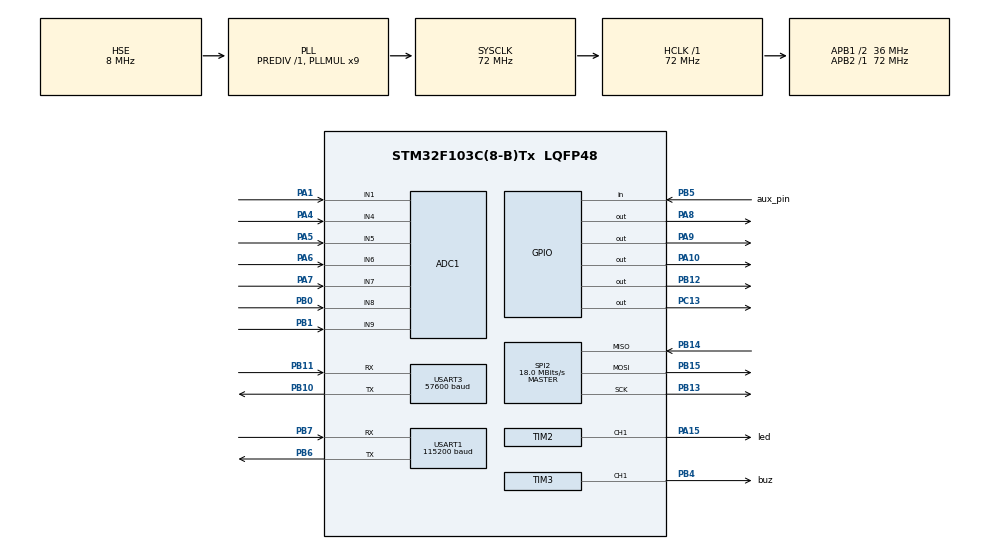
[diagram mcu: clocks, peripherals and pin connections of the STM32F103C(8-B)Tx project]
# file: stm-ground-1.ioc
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ADC1.Channel-1\#ChannelRegularConversion=ADC_CHANNEL_VREFINT
ADC1.Channel-2\#ChannelRegularConversion=ADC_CHANNEL_4
ADC1.Channel-3\#ChannelRegularConversion=ADC_CHANNEL_5
ADC1.Channel-4\#ChannelRegularConversion=ADC_CHANNEL_6
ADC1.Channel-5\#ChannelRegularConversion=ADC_CHANNEL_7
ADC1.Channel-6\#ChannelRegularConversion=ADC_CHANNEL_8
ADC1.Channel-7\#ChannelRegularConversion=ADC_CHANNEL_9
ADC1.Channel-8\#ChannelRegularConversion=ADC_CHANNEL_1
ADC1.NbrOfConversion=8
ADC1.NbrOfConversionFlag=1
ADC1.Rank-1\#ChannelRegularConversion=1
ADC1.Rank-2\#ChannelRegularConversion=2
ADC1.Rank-3\#ChannelRegularConversion=3
ADC1.Rank-4\#ChannelRegularConversion=4
ADC1.Rank-5\#ChannelRegularConversion=5
ADC1.Rank-6\#ChannelRegularConversion=6
ADC1.Rank-7\#ChannelRegularConversion=7
ADC1.Rank-8\#ChannelRegularConversion=8
ADC1.SamplingTime-1\#ChannelRegularConversion=ADC_SAMPLETIME_41CYCLES_5
ADC1.SamplingTime-2\#ChannelRegularConversion=ADC_SAMPLETIME_41CYCLES_5
ADC1.SamplingTime-3\#ChannelRegularConversion=ADC_SAMPLETIME_41CYCLES_5
ADC1.SamplingTime-4\#ChannelRegularConversion=ADC_SAMPLETIME_41CYCLES_5
ADC1.SamplingTime-5\#ChannelRegularConversion=ADC_SAMPLETIME_41CYCLES_5
ADC1.SamplingTime-6\#ChannelRegularConversion=ADC_SAMPLETIME_41CYCLES_5
ADC1.SamplingTime-7\#ChannelRegularConversion=ADC_SAMPLETIME_41CYCLES_5
ADC1.SamplingTime-8\#ChannelRegularConversion=ADC_SAMPLETIME_41CYCLES_5
ADC1.master=1
Dma.ADC1.1.Direction=DMA_PERIPH_TO_MEMORY
Dma.ADC1.1.Instance=DMA1_Channel1
Dma.ADC1.1.MemDataAlignment=DMA_MDATAALIGN_HALFWORD
Dma.ADC1.1.MemInc=DMA_MINC_ENABLE
Dma.ADC1.1.Mode=DMA_NORMAL
Dma.ADC1.1.PeriphDataAlignment=DMA_PDATAALIGN_HALFWORD
Dma.ADC1.1.PeriphInc=DMA_PINC_DISABLE
Dma.ADC1.1.Priority=DMA_PRIORITY_LOW
Dma.Request0=SPI2_TX
Dma.Request1=ADC1
Dma.SPI2_TX.0.Direction=DMA_MEMORY_TO_PERIPH
Dma.SPI2_TX.0.Instance=DMA1_Channel5
Dma.SPI2_TX.0.MemDataAlignment=DMA_MDATAALIGN_BYTE
Dma.SPI2_TX.0.MemInc=DMA_MINC_ENABLE
Dma.SPI2_TX.0.Mode=DMA_NORMAL
Dma.SPI2_TX.0.PeriphDataAlignment=DMA_PDATAALIGN_BYTE
Dma.SPI2_TX.0.PeriphInc=DMA_PINC_DISABLE
Dma.SPI2_TX.0.Priority=DMA_PRIORITY_LOW
Mcu.Family=STM32F1
Mcu.Name=STM32F103C(8-B)Tx
Mcu.Package=LQFP48
NVIC.DMA1_Channel1_IRQn=true\:0\:0\:false\:false\:true\:false\:true\:true
NVIC.DMA1_Channel5_IRQn=true\:0\:0\:false\:false\:true\:false\:true\:true
NVIC.PriorityGroup=NVIC_PRIORITYGROUP_4
NVIC.SPI2_IRQn=true\:0\:0\:false\:false\:true\:true\:true\:true
NVIC.TIM2_IRQn=true\:0\:0\:false\:false\:true\:true\:true\:true
NVIC.USART1_IRQn=true\:0\:0\:false\:false\:true\:true\:true\:true
NVIC.USART3_IRQn=true\:0\:0\:false\:false\:true\:true\:true\:true
PA1.Signal=ADCx_IN1
PA10.Signal=GPIO_Output
PA13.Mode=Trace_Asynchronous_SW
PA13.Signal=SYS_JTMS-SWDIO
PA14.Mode=Trace_Asynchronous_SW
PA14.Signal=SYS_JTCK-SWCLK
PA15.GPIO_Label=led
PA15.Signal=S_TIM2_CH1_ETR
PA4.Signal=ADCx_IN4
PA5.Signal=ADCx_IN5
PA6.Signal=ADCx_IN6
PA7.Signal=ADCx_IN7
PA8.Signal=GPIO_Output
PA9.Signal=GPIO_Output
PB0.Signal=ADCx_IN8
PB1.Signal=ADCx_IN9
PB10.Mode=Asynchronous
PB10.Signal=USART3_TX
PB11.Mode=Asynchronous
PB11.Signal=USART3_RX
PB12.Signal=GPIO_Output
PB13.Mode=Full_Duplex_Master
PB13.Signal=SPI2_SCK
PB14.Mode=Full_Duplex_Master
PB14.Signal=SPI2_MISO
PB15.Mode=Full_Duplex_Master
PB15.Signal=SPI2_MOSI
PB3.Mode=Trace_Asynchronous_SW
PB3.Signal=SYS_JTDO-TRACESWO
PB4.GPIO_Label=buz
PB4.Signal=S_TIM3_CH1
PB5.GPIO_Label=aux_pin
PB5.Signal=GPIO_Input
PB6.Mode=Asynchronous
PB6.Signal=USART1_TX
PB7.Mode=Asynchronous
PB7.Signal=USART1_RX
PC13-TAMPER-RTC.Signal=GPIO_Output
PD0-OSC_IN.Mode=HSE-External-Oscillator
PD0-OSC_IN.Signal=RCC_OSC_IN
PD1-OSC_OUT.Mode=HSE-External-Oscillator
PD1-OSC_OUT.Signal=RCC_OSC_OUT
ProjectManager.HeapSize=0x200
ProjectManager.StackSize=0x400
ProjectManager.TargetToolchain=STM32CubeIDE
RCC.ADCPresc=RCC_ADCPCLK2_DIV6
RCC.AHBFreq_Value=72000000
RCC.APB1CLKDivider=RCC_HCLK_DIV2
RCC.APB1Freq_Value=36000000
RCC.APB1TimFreq_Value=72000000
RCC.APB2Freq_Value=72000000
RCC.APB2TimFreq_Value=72000000
RCC.HCLKFreq_Value=72000000
RCC.PLLMUL=RCC_PLL_MUL9
RCC.PLLSourceVirtual=RCC_PLLSOURCE_HSE
RCC.SYSCLKFreq_VALUE=72000000
RCC.SYSCLKSource=RCC_SYSCLKSOURCE_PLLCLK
RCC.USBFreq_Value=72000000
SH.ADCx_IN1.0=ADC1_IN1,IN1
SH.ADCx_IN4.0=ADC1_IN4,IN4
SH.ADCx_IN5.0=ADC1_IN5,IN5
SH.ADCx_IN6.0=ADC1_IN6,IN6
SH.ADCx_IN7.0=ADC1_IN7,IN7
SH.ADCx_IN8.0=ADC1_IN8,IN8
SH.ADCx_IN9.0=ADC1_IN9,IN9
SH.S_TIM2_CH1_ETR.0=TIM2_CH1,PWM Generation1 CH1
SH.S_TIM3_CH1.0=TIM3_CH1,PWM Generation1 CH1
SPI2.BaudRatePrescaler=SPI_BAUDRATEPRESCALER_2
SPI2.CLKPolarity=SPI_POLARITY_LOW
SPI2.CalculateBaudRate=18.0 MBits/s
SPI2.Direction=SPI_DIRECTION_2LINES
SPI2.Mode=SPI_MODE_MASTER
SPI2.VirtualType=VM_MASTER
TIM2.Channel-PWM\ Generation1\ CH1=TIM_CHANNEL_1
TIM2.Period=999
TIM2.Prescaler=71
TIM3.Channel-PWM\ Generation1\ CH1=TIM_CHANNEL_1
TIM3.Period=249
TIM3.Prescaler=71
USART1.BaudRate=115200
USART1.VirtualMode=VM_ASYNC
USART3.BaudRate=57600
USART3.VirtualMode=VM_ASYNC
VP_ADC1_Vref_Input.Mode=IN-Vrefint
VP_TIM2_VS_ClockSourceINT.Mode=Internal
VP_TIM3_VS_ClockSourceINT.Mode=Internal
board=custom

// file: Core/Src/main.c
/* USER CODE BEGIN Header */
/**
  ******************************************************************************
  * @file           : main.c
  * @brief          : Main program body
  ******************************************************************************
  * @attention
  *
  * Copyright (c) 2025 STMicroelectronics.
  * All rights reserved.
  *
  * This software is licensed under terms that can be found in the LICENSE file
  * in the root directory of this software component.
  * If no LICENSE file comes with this software, it is provided AS-IS.
  *
  ******************************************************************************
  */
/* USER CODE END Header */
#include "main.h"

/* USER CODE BEGIN PTD */
int app();
__attribute__((weak)) int _write(int file, char* ptr, int len)
{
    (void)file;
    int DataIdx;

    for (DataIdx = 0; DataIdx < len; DataIdx++)
    {
        ITM_SendChar(*ptr++);
    }
    return len;
}
/* USER CODE END PTD */

ADC_HandleTypeDef hadc1;
DMA_HandleTypeDef hdma_adc1;

SPI_HandleTypeDef hspi2;
DMA_HandleTypeDef hdma_spi2_tx;

TIM_HandleTypeDef htim2;
TIM_HandleTypeDef htim3;

UART_HandleTypeDef huart1;
UART_HandleTypeDef huart3;

void SystemClock_Config(void);
static void MX_GPIO_Init(void);
static void MX_DMA_Init(void);
static void MX_SPI2_Init(void);
static void MX_USART1_UART_Init(void);
static void MX_ADC1_Init(void);
static void MX_USART3_UART_Init(void);
static void MX_TIM2_Init(void);
static void MX_TIM3_Init(void);

int main(void)
{

  /* MCU Configuration--------------------------------------------------------*/

  /* Reset of all peripherals, Initializes the Flash interface and the Systick. */
  HAL_Init();

  /* Configure the system clock */
  SystemClock_Config();

  /* Initialize all configured peripherals */
  MX_GPIO_Init();
  MX_DMA_Init();
  MX_SPI2_Init();
  MX_USART1_UART_Init();
  MX_ADC1_Init();
  MX_USART3_UART_Init();
  MX_TIM2_Init();
  MX_TIM3_Init();
  /* USER CODE BEGIN 2 */
  app();
  /* USER CODE END 2 */

  /* Infinite loop */
  while (1)
  {

  }
}

void SystemClock_Config(void)
{
  RCC_OscInitTypeDef RCC_OscInitStruct = {0};
  RCC_ClkInitTypeDef RCC_ClkInitStruct = {0};
  RCC_PeriphCLKInitTypeDef PeriphClkInit = {0};

  /** Initializes the RCC Oscillators according to the specified parameters
  * in the RCC_OscInitTypeDef structure.
  */
  RCC_OscInitStruct.OscillatorType = RCC_OSCILLATORTYPE_HSE;
  RCC_OscInitStruct.HSEState = RCC_HSE_ON;
  RCC_OscInitStruct.HSEPredivValue = RCC_HSE_PREDIV_DIV1;
  RCC_OscInitStruct.HSIState = RCC_HSI_ON;
  RCC_OscInitStruct.PLL.PLLState = RCC_PLL_ON;
  RCC_OscInitStruct.PLL.PLLSource = RCC_PLLSOURCE_HSE;
  RCC_OscInitStruct.PLL.PLLMUL = RCC_PLL_MUL9;
  if (HAL_RCC_OscConfig(&RCC_OscInitStruct) != HAL_OK)
  {
    Error_Handler();
  }

  /** Initializes the CPU, AHB and APB buses clocks
  */
  RCC_ClkInitStruct.ClockType = RCC_CLOCKTYPE_HCLK|RCC_CLOCKTYPE_SYSCLK
                              |RCC_CLOCKTYPE_PCLK1|RCC_CLOCKTYPE_PCLK2;
  RCC_ClkInitStruct.SYSCLKSource = RCC_SYSCLKSOURCE_PLLCLK;
  RCC_ClkInitStruct.AHBCLKDivider = RCC_SYSCLK_DIV1;
  RCC_ClkInitStruct.APB1CLKDivider = RCC_HCLK_DIV2;
  RCC_ClkInitStruct.APB2CLKDivider = RCC_HCLK_DIV1;

  if (HAL_RCC_ClockConfig(&RCC_ClkInitStruct, FLASH_LATENCY_2) != HAL_OK)
  {
    Error_Handler();
  }
  PeriphClkInit.PeriphClockSelection = RCC_PERIPHCLK_ADC;
  PeriphClkInit.AdcClockSelection = RCC_ADCPCLK2_DIV6;
  if (HAL_RCCEx_PeriphCLKConfig(&PeriphClkInit) != HAL_OK)
  {
    Error_Handler();
  }
}

static void MX_ADC1_Init(void)
{

  ADC_ChannelConfTypeDef sConfig = {0};

  /** Common config
  */
  hadc1.Instance = ADC1;
  hadc1.Init.ScanConvMode = ADC_SCAN_ENABLE;
  hadc1.Init.ContinuousConvMode = DISABLE;
  hadc1.Init.DiscontinuousConvMode = DISABLE;
  hadc1.Init.ExternalTrigConv = ADC_SOFTWARE_START;
  hadc1.Init.DataAlign = ADC_DATAALIGN_RIGHT;
  hadc1.Init.NbrOfConversion = 8;
  if (HAL_ADC_Init(&hadc1) != HAL_OK)
  {
    Error_Handler();
  }

  /** Configure Regular Channel
  */
  sConfig.Channel = ADC_CHANNEL_VREFINT;
  sConfig.Rank = ADC_REGULAR_RANK_1;
  sConfig.SamplingTime = ADC_SAMPLETIME_41CYCLES_5;
  if (HAL_ADC_ConfigChannel(&hadc1, &sConfig) != HAL_OK)
  {
    Error_Handler();
  }

  /** Configure Regular Channel
  */
  sConfig.Channel = ADC_CHANNEL_4;
  sConfig.Rank = ADC_REGULAR_RANK_2;
  if (HAL_ADC_ConfigChannel(&hadc1, &sConfig) != HAL_OK)
  {
    Error_Handler();
  }

  /** Configure Regular Channel
  */
  sConfig.Channel = ADC_CHANNEL_5;
  sConfig.Rank = ADC_REGULAR_RANK_3;
  if (HAL_ADC_ConfigChannel(&hadc1, &sConfig) != HAL_OK)
  {
    Error_Handler();
  }

  /** Configure Regular Channel
  */
  sConfig.Channel = ADC_CHANNEL_6;
  sConfig.Rank = ADC_REGULAR_RANK_4;
  if (HAL_ADC_ConfigChannel(&hadc1, &sConfig) != HAL_OK)
  {
    Error_Handler();
  }

  /** Configure Regular Channel
  */
  sConfig.Channel = ADC_CHANNEL_7;
  sConfig.Rank = ADC_REGULAR_RANK_5;
  if (HAL_ADC_ConfigChannel(&hadc1, &sConfig) != HAL_OK)
  {
    Error_Handler();
  }

  /** Configure Regular Channel
  */
  sConfig.Channel = ADC_CHANNEL_8;
  sConfig.Rank = ADC_REGULAR_RANK_6;
  if (HAL_ADC_ConfigChannel(&hadc1, &sConfig) != HAL_OK)
  {
    Error_Handler();
  }

  /** Configure Regular Channel
  */
  sConfig.Channel = ADC_CHANNEL_9;
  sConfig.Rank = ADC_REGULAR_RANK_7;
  if (HAL_ADC_ConfigChannel(&hadc1, &sConfig) != HAL_OK)
  {
    Error_Handler();
  }

  /** Configure Regular Channel
  */
  sConfig.Channel = ADC_CHANNEL_1;
  sConfig.Rank = ADC_REGULAR_RANK_8;
  if (HAL_ADC_ConfigChannel(&hadc1, &sConfig) != HAL_OK)
  {
    Error_Handler();
  }

}

static void MX_SPI2_Init(void)
{

  /* SPI2 parameter configuration*/
  hspi2.Instance = SPI2;
  hspi2.Init.Mode = SPI_MODE_MASTER;
  hspi2.Init.Direction = SPI_DIRECTION_2LINES;
  hspi2.Init.DataSize = SPI_DATASIZE_8BIT;
  hspi2.Init.CLKPolarity = SPI_POLARITY_LOW;
  hspi2.Init.CLKPhase = SPI_PHASE_1EDGE;
  hspi2.Init.NSS = SPI_NSS_SOFT;
  hspi2.Init.BaudRatePrescaler = SPI_BAUDRATEPRESCALER_2;
  hspi2.Init.FirstBit = SPI_FIRSTBIT_MSB;
  hspi2.Init.TIMode = SPI_TIMODE_DISABLE;
  hspi2.Init.CRCCalculation = SPI_CRCCALCULATION_DISABLE;
  hspi2.Init.CRCPolynomial = 10;
  if (HAL_SPI_Init(&hspi2) != HAL_OK)
  {
    Error_Handler();
  }

}

static void MX_TIM2_Init(void)
{

  TIM_ClockConfigTypeDef sClockSourceConfig = {0};
  TIM_MasterConfigTypeDef sMasterConfig = {0};
  TIM_OC_InitTypeDef sConfigOC = {0};

  htim2.Instance = TIM2;
  htim2.Init.Prescaler = 71;
  htim2.Init.CounterMode = TIM_COUNTERMODE_UP;
  htim2.Init.Period = 999;
  htim2.Init.ClockDivision = TIM_CLOCKDIVISION_DIV1;
  htim2.Init.AutoReloadPreload = TIM_AUTORELOAD_PRELOAD_DISABLE;
  if (HAL_TIM_Base_Init(&htim2) != HAL_OK)
  {
    Error_Handler();
  }
  sClockSourceConfig.ClockSource = TIM_CLOCKSOURCE_INTERNAL;
  if (HAL_TIM_ConfigClockSource(&htim2, &sClockSourceConfig) != HAL_OK)
  {
    Error_Handler();
  }
  if (HAL_TIM_PWM_Init(&htim2) != HAL_OK)
  {
    Error_Handler();
  }
  sMasterConfig.MasterOutputTrigger = TIM_TRGO_RESET;
  sMasterConfig.MasterSlaveMode = TIM_MASTERSLAVEMODE_DISABLE;
  if (HAL_TIMEx_MasterConfigSynchronization(&htim2, &sMasterConfig) != HAL_OK)
  {
    Error_Handler();
  }
  sConfigOC.OCMode = TIM_OCMODE_PWM1;
  sConfigOC.Pulse = 0;
  sConfigOC.OCPolarity = TIM_OCPOLARITY_HIGH;
  sConfigOC.OCFastMode = TIM_OCFAST_DISABLE;
  if (HAL_TIM_PWM_ConfigChannel(&htim2, &sConfigOC, TIM_CHANNEL_1) != HAL_OK)
  {
    Error_Handler();
  }
  HAL_TIM_MspPostInit(&htim2);

}

static void MX_TIM3_Init(void)
{

  TIM_ClockConfigTypeDef sClockSourceConfig = {0};
  TIM_MasterConfigTypeDef sMasterConfig = {0};
  TIM_OC_InitTypeDef sConfigOC = {0};

  htim3.Instance = TIM3;
  htim3.Init.Prescaler = 71;
  htim3.Init.CounterMode = TIM_COUNTERMODE_UP;
  htim3.Init.Period = 249;
  htim3.Init.ClockDivision = TIM_CLOCKDIVISION_DIV1;
  htim3.Init.AutoReloadPreload = TIM_AUTORELOAD_PRELOAD_DISABLE;
  if (HAL_TIM_Base_Init(&htim3) != HAL_OK)
  {
    Error_Handler();
  }
  sClockSourceConfig.ClockSource = TIM_CLOCKSOURCE_INTERNAL;
  if (HAL_TIM_ConfigClockSource(&htim3, &sClockSourceConfig) != HAL_OK)
  {
    Error_Handler();
  }
  if (HAL_TIM_PWM_Init(&htim3) != HAL_OK)
  {
    Error_Handler();
  }
  sMasterConfig.MasterOutputTrigger = TIM_TRGO_RESET;
  sMasterConfig.MasterSlaveMode = TIM_MASTERSLAVEMODE_DISABLE;
  if (HAL_TIMEx_MasterConfigSynchronization(&htim3, &sMasterConfig) != HAL_OK)
  {
    Error_Handler();
  }
  sConfigOC.OCMode = TIM_OCMODE_PWM1;
  sConfigOC.Pulse = 0;
  sConfigOC.OCPolarity = TIM_OCPOLARITY_HIGH;
  sConfigOC.OCFastMode = TIM_OCFAST_DISABLE;
  if (HAL_TIM_PWM_ConfigChannel(&htim3, &sConfigOC, TIM_CHANNEL_1) != HAL_OK)
  {
    Error_Handler();
  }
  HAL_TIM_MspPostInit(&htim3);

}

static void MX_USART1_UART_Init(void)
{

  huart1.Instance = USART1;
  huart1.Init.BaudRate = 115200;
  huart1.Init.WordLength = UART_WORDLENGTH_8B;
  huart1.Init.StopBits = UART_STOPBITS_1;
  huart1.Init.Parity = UART_PARITY_NONE;
  huart1.Init.Mode = UART_MODE_TX_RX;
  huart1.Init.HwFlowCtl = UART_HWCONTROL_NONE;
  huart1.Init.OverSampling = UART_OVERSAMPLING_16;
  if (HAL_UART_Init(&huart1) != HAL_OK)
  {
    Error_Handler();
  }

}

static void MX_USART3_UART_Init(void)
{

  huart3.Instance = USART3;
  huart3.Init.BaudRate = 57600;
  huart3.Init.WordLength = UART_WORDLENGTH_8B;
  huart3.Init.StopBits = UART_STOPBITS_1;
  huart3.Init.Parity = UART_PARITY_NONE;
  huart3.Init.Mode = UART_MODE_TX_RX;
  huart3.Init.HwFlowCtl = UART_HWCONTROL_NONE;
  huart3.Init.OverSampling = UART_OVERSAMPLING_16;
  if (HAL_UART_Init(&huart3) != HAL_OK)
  {
    Error_Handler();
  }

}

static void MX_DMA_Init(void)
{

  /* DMA controller clock enable */
  __HAL_RCC_DMA1_CLK_ENABLE();

  /* DMA interrupt init */
  /* DMA1_Channel1_IRQn interrupt configuration */
  HAL_NVIC_SetPriority(DMA1_Channel1_IRQn, 0, 0);
  HAL_NVIC_EnableIRQ(DMA1_Channel1_IRQn);
  /* DMA1_Channel5_IRQn interrupt configuration */
  HAL_NVIC_SetPriority(DMA1_Channel5_IRQn, 0, 0);
  HAL_NVIC_EnableIRQ(DMA1_Channel5_IRQn);

}

static void MX_GPIO_Init(void)
{
  GPIO_InitTypeDef GPIO_InitStruct = {0};

  /* GPIO Ports Clock Enable */
  __HAL_RCC_GPIOC_CLK_ENABLE();
  __HAL_RCC_GPIOD_CLK_ENABLE();
  __HAL_RCC_GPIOA_CLK_ENABLE();
  __HAL_RCC_GPIOB_CLK_ENABLE();

  /*Configure GPIO pin Output Level */
  HAL_GPIO_WritePin(GPIOC, GPIO_PIN_13, GPIO_PIN_RESET);

  /*Configure GPIO pin Output Level */
  HAL_GPIO_WritePin(GPIOB, GPIO_PIN_12, GPIO_PIN_RESET);

  /*Configure GPIO pin Output Level */
  HAL_GPIO_WritePin(GPIOA, GPIO_PIN_8|GPIO_PIN_9|GPIO_PIN_10, GPIO_PIN_RESET);

  /*Configure GPIO pin : PC13 */
  GPIO_InitStruct.Pin = GPIO_PIN_13;
  GPIO_InitStruct.Mode = GPIO_MODE_OUTPUT_PP;
  GPIO_InitStruct.Pull = GPIO_NOPULL;
  GPIO_InitStruct.Speed = GPIO_SPEED_FREQ_LOW;
  HAL_GPIO_Init(GPIOC, &GPIO_InitStruct);

  /*Configure GPIO pin : PB12 */
  GPIO_InitStruct.Pin = GPIO_PIN_12;
  GPIO_InitStruct.Mode = GPIO_MODE_OUTPUT_PP;
  GPIO_InitStruct.Pull = GPIO_NOPULL;
  GPIO_InitStruct.Speed = GPIO_SPEED_FREQ_LOW;
  HAL_GPIO_Init(GPIOB, &GPIO_InitStruct);

  /*Configure GPIO pins : PA8 PA9 PA10 */
  GPIO_InitStruct.Pin = GPIO_PIN_8|GPIO_PIN_9|GPIO_PIN_10;
  GPIO_InitStruct.Mode = GPIO_MODE_OUTPUT_PP;
  GPIO_InitStruct.Pull = GPIO_NOPULL;
  GPIO_InitStruct.Speed = GPIO_SPEED_FREQ_LOW;
  HAL_GPIO_Init(GPIOA, &GPIO_InitStruct);

  /*Configure GPIO pin : aux_pin_Pin */
  GPIO_InitStruct.Pin = aux_pin_Pin;
  GPIO_InitStruct.Mode = GPIO_MODE_INPUT;
  GPIO_InitStruct.Pull = GPIO_NOPULL;
  HAL_GPIO_Init(aux_pin_GPIO_Port, &GPIO_InitStruct);

}

void Error_Handler(void)
{
  __disable_irq();
  while (1)
  {
  }
}
